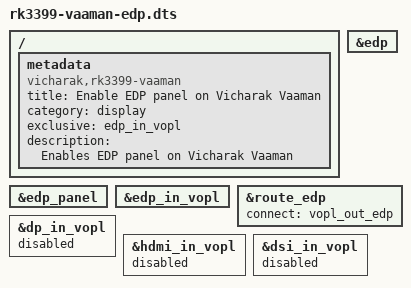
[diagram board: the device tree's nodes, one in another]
// SPDX-License-Identifier: GPL-2.0+
// Copyright (C) 2023 Vicharak Computers LLP

/dts-v1/;
/plugin/;

/ {
	metadata {
		title = "Enable EDP panel on Vicharak Vaaman";
		compatible = "vicharak,rk3399-vaaman", "rockchip,rk3399";
		category = "display";
		exclusive = "edp_in_vopl";
		description = "Enables EDP panel on Vicharak Vaaman";
	};

	fragment@0 {
		target = <&edp_panel>;

		__overlay__ {
			status = "okay";
		};
	};

	fragment@1 {
		target = <&edp>;

		__overlay__ {
			status = "okay";
		};
	};

	fragment@2 {
		target = <&edp_in_vopl>;

		__overlay__ {
			status = "okay";
		};
	};

	fragment@3 {
		target = <&route_edp>;

		__overlay__ {
			status = "okay";
			connect = <&vopl_out_edp>;
		};
	};

	fragment@4 {
		target = <&dp_in_vopl>;

		__overlay__ {
			status = "disabled";
		};
	};

	fragment@5 {
		target = <&hdmi_in_vopl>;

		__overlay__ {
			status = "disabled";
		};
	};

	fragment@6 {
		target = <&dsi_in_vopl>;

		__overlay__ {
			status = "disabled";
		};
	};
};
